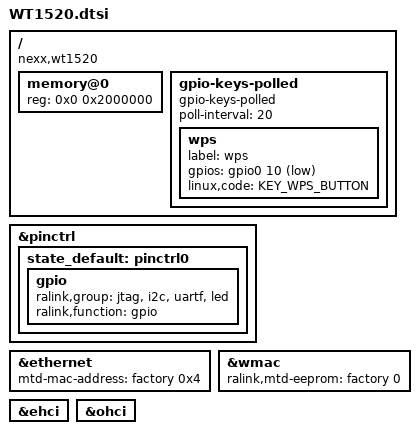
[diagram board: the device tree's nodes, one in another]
#include "rt5350.dtsi"

#include <dt-bindings/gpio/gpio.h>
#include <dt-bindings/input/input.h>

/ {
	compatible = "nexx,wt1520", "ralink,rt5350-soc";

	memory@0 {
		device_type = "memory";
		reg = <0x0 0x2000000>;
	};

	gpio-keys-polled {
		compatible = "gpio-keys-polled";
		#address-cells = <1>;
		#size-cells = <0>;
		poll-interval = <20>;

		wps {
			label = "wps";
			gpios = <&gpio0 10 GPIO_ACTIVE_LOW>;
			linux,code = <KEY_WPS_BUTTON>;
		};
	};
};

&pinctrl {
	state_default: pinctrl0 {
		gpio {
			ralink,group = "jtag", "i2c", "uartf", "led";
			ralink,function = "gpio";
		};
	};
};

&ethernet {
	mtd-mac-address = <&factory 0x4>;
};

&wmac {
	ralink,mtd-eeprom = <&factory 0>;
};

&ehci {
	status = "okay";
};

&ohci {
	status = "okay";
};
